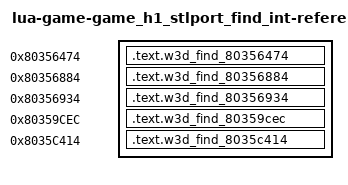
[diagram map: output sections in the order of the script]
/* Generated reference-only placements. All bodies are source-built. */
OUTPUT_FORMAT("elf32-powerpc")
OUTPUT_ARCH(powerpc)
ENTRY(w3d_find_80356474)
_SDA_BASE_ = 0x804b2540;
_SDA2_BASE_ = 0x804c2540;
SECTIONS {
  .text.w3d_find_80356474 0x80356474 : { *(.text.w3d_find_80356474) }
  .text.w3d_find_80356884 0x80356884 : { *(.text.w3d_find_80356884) }
  .text.w3d_find_80356934 0x80356934 : { *(.text.w3d_find_80356934) }
  .text.w3d_find_80359cec 0x80359cec : { *(.text.w3d_find_80359cec) }
  .text.w3d_find_8035c414 0x8035c414 : { *(.text.w3d_find_8035c414) }
  /DISCARD/ : { *(.text*) *(.rodata*) *(.data*) *(.bss*) *(.sdata*) *(.sbss*) *(.comment) }
}
